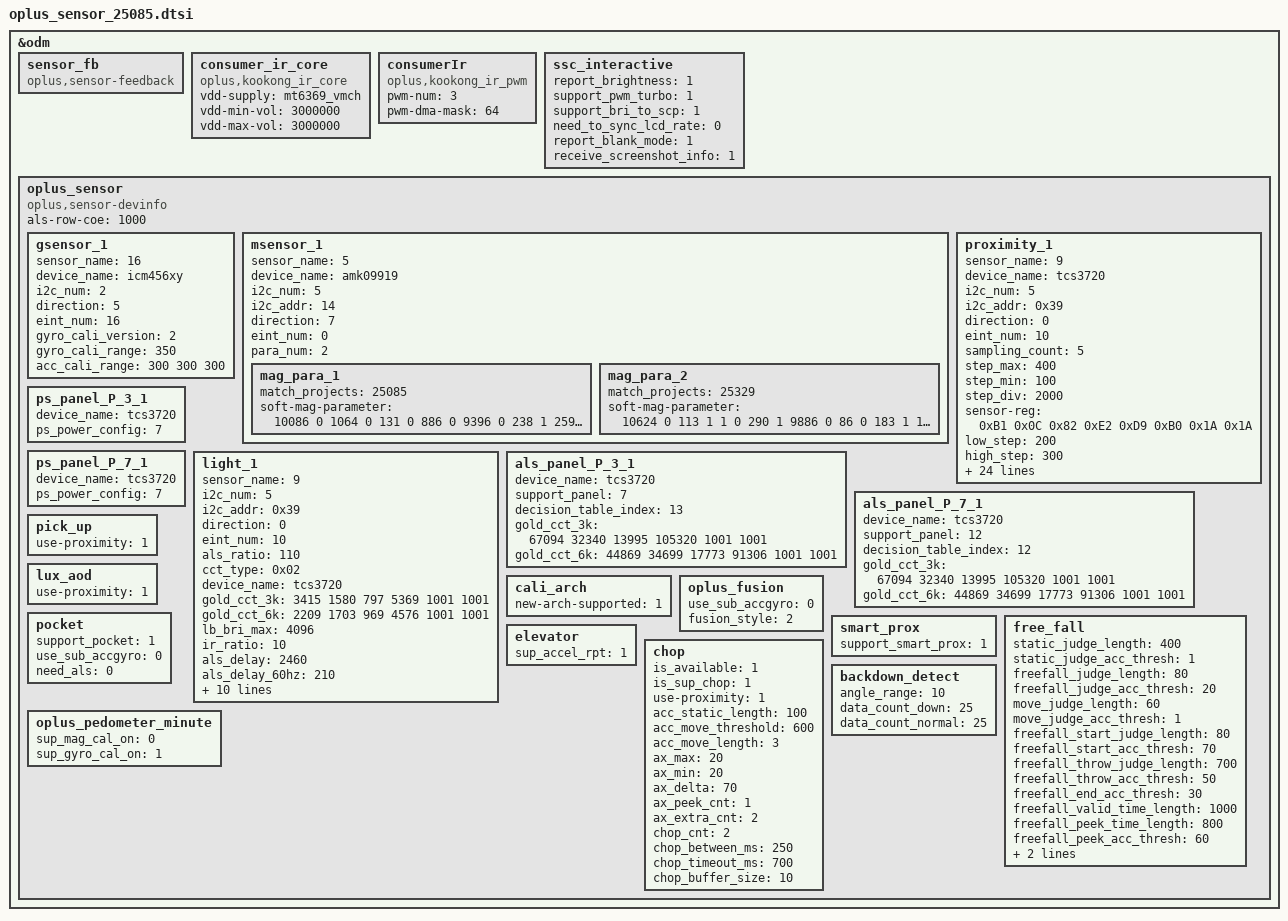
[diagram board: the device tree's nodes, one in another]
&odm {
	sensor_fb: sensor_fb {
		compatible = "oplus,sensor-feedback";
	};
	consumer_ir_core: consumer_ir_core {
		compatible = "oplus,kookong_ir_core";
		status = "okay";
		vdd-supply = <&mt6369_vmch>;
		vdd-min-vol = <3000000>;
		vdd-max-vol = <3000000>;
	};
	consumerIr: consumerIr {
		compatible = "oplus,kookong_ir_pwm";
		status = "okay";
		pwm-num = <3>;
		pwm-dma-mask = <64>;
	};
	ssc_interactive: ssc_interactive {
		report_brightness = <1>;
		support_pwm_turbo = <1>;
		support_bri_to_scp = <1>;
		need_to_sync_lcd_rate = <0>;
		report_blank_mode = <1>;
        receive_screenshot_info = <1>;
	};
	oplus_sensor:oplus_sensor {
		compatible = "oplus,sensor-devinfo";
		als-row-coe = <1000>;
		/* sensor start */
		/*
		enum {
			LIS3DH,
			LSM6DS3,
			BMI160,
			LIS2HH12,
			LSM6DSM,
			BMI2XY,
			LSM6DSO,
			ICM4X6XX,
			ICM4263X,
			ICM4N607,
			BMI22X,
			SC7A20,
			MC34X9,
		};
		*/
		gsensor_1: gsensor_1 {
			status = "okay";
			sensor_name = <16>; // ICM456XY
			device_name = "icm456xy";
			i2c_num = <2>;
			direction = <5>;
			eint_num = <16>;
			gyro_cali_version= <2>;
			gyro_cali_range =<350>;
			acc_cali_range= <300 300 300>;
		};

		/*
		enum {
			AKM09911,
			MMC3530,
			MMC5603,
			MXG4300,
			AKM09918,
		};
		*/
		msensor_1: msensor_1 {
			status = "okay";
			sensor_name = <5>;//AKM09919
			device_name = "amk09919";
			i2c_num = <5>;
			i2c_addr = <14>;
			direction = <7>;
			eint_num = <0>;
			para_num = <2>;
			mag_para_1 {
				match_projects = <25085>;//NFC
				soft-mag-parameter = <10086 0 1064 0 131 0 886 0 9396 0 238 1 259 0 161 0 10798 0>;
			};
			mag_para_2 {
				match_projects = <25329>;//NO NFC
				soft-mag-parameter = <10624 0 113 1 1 0 290 1 9886 0 86 0 183 1 191 0 10934 0>;
			};
		};

		/*
		enum {
			TMD2725,
			APSD9922,
			STK3335,
			STK3331,
			STK2232,
			TCS3701,
			STK32600,
			STK33502,
			MN78911,
			TCS3720,
			SIP3515,
			STK3329,
			LTR569,
			SIP3510,
			SIP3625,
		};
		*/

		proximity_1: proximity_1 {
			status = "okay";
			sensor_name = <9>;//TCS3720
			device_name = "tcs3720";
			i2c_num = <5>;
			i2c_addr = <0x39>;
			direction = <0>;
			eint_num = <10>;
			sampling_count = <5>;
			step_max = <400>;
			step_min = <100>;
			step_div = <2000>;
			sensor-reg = <0xB1 0x0C 0x82 0xE2 0xD9 0xB0 0x1A 0x1A>;
			low_step = <200>;
			high_step = <300>;
			low_limit = <1000>;
			high_limit = <1250>;
			dirty_low_step = <900>;
			dirty_high_step = <1100>;
			ps_dirty_limit = <8000>;
			ps_ir_limit = <500>;
			ps_adjust_min = <0>;
			ps_adjust_max = <1250>;
			anti_shake_delta = <150>;
			dynamic_cali_max = <5000>;
			raw2offset_radio = <1000>;
			offset_max = <16000>;
			offset_range_min = <0>;
			offset_range_max = <65534>;
			force_cali_limit = <16383>;
			cali_jitter_limit = <80>;
			cal_offset_margin = <8000>;
			60hz_psd_us = <7800>;
			90hz_psd_us = <7800>;
			120hz_psd_us = <7800>;
			ps_check_num = <3>;
			ps_mid_filter = <0>;
			need_to_sync_lcd_rate = <0>;
			dmc_flt_thr = <100>;
		};
                ps_panel_P_3_1: ps_panel_P_3_1 {
                        status = "okay";
                        device_name = "tcs3720";
                        ps_power_config = <7>;
                };
                ps_panel_P_7_1: ps_panel_P_7_1 {
                        status = "okay";
                        device_name = "tcs3720";
                        ps_power_config = <7>;
                };
		light_1: light_1 {
			status = "okay";
			sensor_name = <9>;//TCS3720
			i2c_num = <5>;
			i2c_addr = <0x39>;
			direction = <0>;
			eint_num = <10>;
			als_ratio = <110>;
			cct_type = <0x02>; //0x01 CCT_NORMAL 0x02 CCT_WISE
			device_name = "tcs3720";
			gold_cct_3k = <3415 1580 797 5369 1001 1001>;
			gold_cct_6k = <2209 1703 969 4576 1001 1001>;
			lb_bri_max = <4096>;
			ir_ratio = <10>; // *1000
			als_delay = <2460>;
			als_delay_60hz = <210>;
			als_delay_90hz = <212>;
			als_delay_120hz = <219>;
			available_sensor = <14>;
			gold_cct_factor = <1000 1000 1000 1000 1000 1000>;
			high_pwm_cct = <1>;
			als_timer_ms = <100>;
			als_buffer_length = <2>;
			need_gain_cali = <1>;
                        lux_thod = <2000>; // add for high light mode
                        strong_ir_thod = <15>; // *100 add for high light mode
		};
                als_panel_P_3_1: als_panel_P_3_1 {
                        status = "okay";
                        device_name = "tcs3720";
                        support_panel = <7>;
                        decision_table_index = <13>;
                        gold_cct_3k = <67094 32340 13995 105320 1001 1001>;
                        gold_cct_6k = <44869 34699 17773 91306 1001 1001>;
                };
                als_panel_P_7_1: als_panel_P_7_1 {
                        status = "okay";
                        device_name = "tcs3720";
                        support_panel = <12>;
                        decision_table_index = <12>;
                        gold_cct_3k = <67094 32340 13995 105320 1001 1001>;
                        gold_cct_6k = <44869 34699 17773 91306 1001 1001>;
                };

		pick_up: pick_up {
			status = "okay";
			use-proximity = <1>;
		};
		lux_aod: lux_aod {
			status = "okay";
			use-proximity = <1>;
		};
		cali_arch: cali_arch {
			status = "okay";
			new-arch-supported = <1>;
		};
		oplus_fusion: oplus_fusion {
			status = "okay";
			use_sub_accgyro = <0>;
                        fusion_style = <2>; // 0:vendor fusion; 1:oppo fusion; 2:mix fusion
		};
		smart_prox: smart_prox {
			status = "okay";
			support_smart_prox = <1>;
		};
                pocket: pocket {
			status = "okay";
			support_pocket = <1>;
			use_sub_accgyro = <0>;
			need_als = <0>;
		};
		free_fall: free_fall{
			status = "okay";
			static_judge_length = <400>;
			static_judge_acc_thresh = <1>;
			freefall_judge_length = <80>;
			freefall_judge_acc_thresh = <20>;
			move_judge_length = <60>;
			move_judge_acc_thresh = <1>;
			freefall_start_judge_length  = <80>;
			freefall_start_acc_thresh = <70>;
			freefall_throw_judge_length = <700>;
			freefall_throw_acc_thresh = <50>;
			freefall_end_acc_thresh = <30>;
			freefall_valid_time_length = <1000>;
			freefall_peek_time_length = <800>;
			freefall_peek_acc_thresh = <60>;
			freefall_material_thresh = <900>;
			valid_peek_interval_thresh = <10000>;
		};
		elevator: elevator{
			status = "okay";
			sup_accel_rpt = <1>;
		};
		chop: chop {
			status = "okay";
			is_available = <1>;
			is_sup_chop = <1>;
			use-proximity = <1>;

			acc_static_length = <100>;
			acc_move_threshold = <600>;
			acc_move_length = <3>;
			ax_max = <20>;
			ax_min = <20>;
			ax_delta = <70>;
			ax_peek_cnt = <1>;
			ax_extra_cnt = <2>;
			chop_cnt = <2>;
			chop_between_ms = <250>;
			chop_timeout_ms = <700>;
			chop_buffer_size = <10>;
		};
		backdown_detect: backdown_detect{
			status = "okay";
			angle_range = <10>; // degree
			data_count_down = <25>; //data count down
			data_count_normal = <25>; //data count normal
		};
		oplus_pedometer_minute: oplus_pedometer_minute{
			status = "okay";
			sup_mag_cal_on = <0>;
			sup_gyro_cal_on = <1>;
		};
	};
/* sensor end */
};
